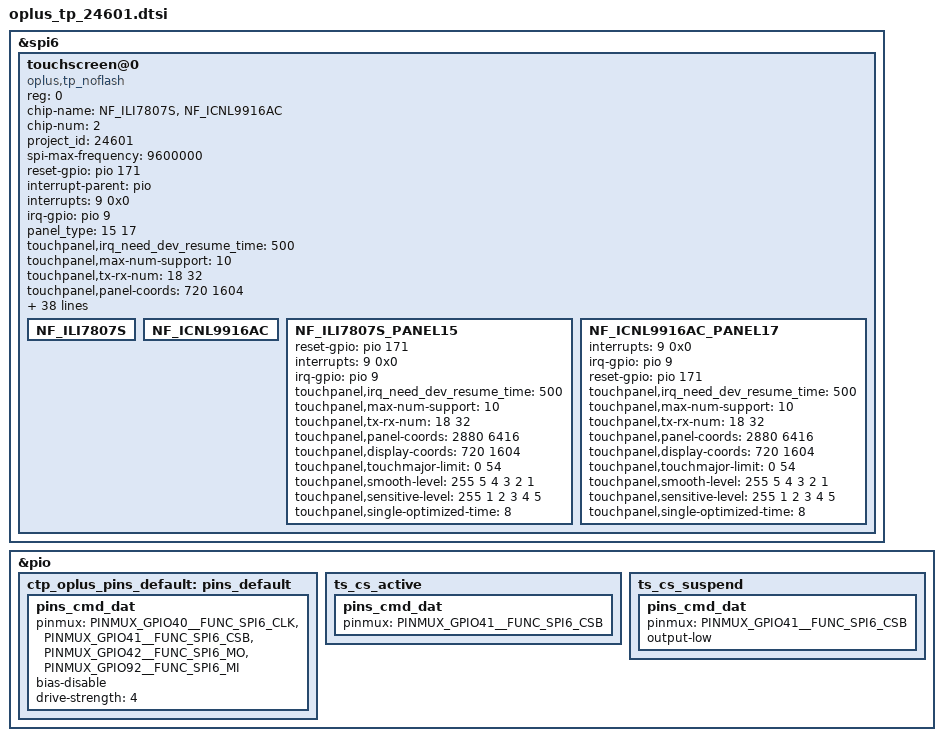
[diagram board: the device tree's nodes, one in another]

#include "mediatek/oplus-24601-tpfw.dtsi"
&spi6 {
	status = "okay";
	#address-cells = <1>;
	#size-cells = <0>;
	touchscreen@0 {
		compatible = "oplus,tp_noflash";
		reg = <0>;
		chip-name = "NF_ILI7807S","NF_ICNL9916AC";
		status = "ok";
		chip-num = <2>;

		project_id = <24601>;
		spi-max-frequency = <9600000>;    /*4800000,9600000,15000000,19200000*/
		reset-gpio = <&pio 171 0x00>;
		interrupt-parent = <&pio>;
		interrupts = <9  0x0>;
		irq-gpio = <&pio 9 0x2002>;

		panel_type = <15 17>;  /*type:20 HUIKE type:19 TONGXINGDA*/
		touchpanel,irq_need_dev_resume_time = <500>;
		touchpanel,max-num-support = <10>;
		touchpanel,tx-rx-num = <18 32>;			/*hd:18  32*/
		touchpanel,panel-coords = <720 1604>;
		touchpanel,display-coords = <720 1604>;	/*hd:720 1612*/
		touchpanel,touchmajor-limit = <0 54>;
		platform_support_project = <24601 24615 24617 24683 24722 24723 24727 24745 24746 24747>;
		platform_support_project_dir = <24601 24601 24601 24601 24601 24601 24601 24601 24601 24601>;
		platform_support_project_commandline ="oplus24601_hkc_ili9883c_hd_dsi_vdo_lcm_drv","oplus24601_djn_icnl9916ac_hd_dsi_vdo_lcm_drv";	/* hd*/
		firmware_name = "0xAB879HK00","0xAB879DJ00";
		pinctrl-names = "default", "pin_cs_high","pin_cs_low";
		pinctrl-0 = <&ctp_oplus_pins_default>;
		pinctrl-1 = <&ts_cs_active>;
		pinctrl-2 = <&ts_cs_suspend>;

		touchpanel,smooth-level = <255 5 4 3 2 1>;
		touchpanel,sensitive-level = <255 1 2 3 4 5>;
		touchpanel,single-optimized-time = <8>;

		incell_screen;
		irq_need_dev_resume_ok;
		fw_edge_limit_support;
		black_gesture_support;
		charger_pump_support;
		//headset_pump_support;
		esd_handle_support;
		//spurious_fingerprint_support;
		//lcd_trigger_fp_check;
		black_gesture_test_support;
		noflash_support;
		smart_gesture_support;
		pressure_report_support;
		fw_update_app_support;
		game_switch_support;
		drlimit_remove_support;
		lcd_trigger_load_tp_fw_support;
		suspend_gesture_cfg;
		//fw_update_in_probe_with_headfile;
		health_monitor_support;
		//auto_test_force_pass_support;
		exception_upload_support;
		report_rate_white_list_support;
		touchpanel,button-type = <4>;
		palm_to_sleep_support;
		diaphragm_touch_support;
		waterproof_support;

		NF_ILI7807S {

		};

		NF_ICNL9916AC {

		};
		NF_ILI7807S_PANEL15 {
			reset-gpio = <&pio 171 0x00>;
			interrupts = <9  0x0>;
			irq-gpio = <&pio 9 0x2002>;

			touchpanel,irq_need_dev_resume_time = <500>;
			touchpanel,max-num-support = <10>;
			touchpanel,tx-rx-num = <18 32>;			/*hd:18  32*/
			touchpanel,panel-coords = <2880 6416>;
			touchpanel,display-coords = <720 1604>;	/*hd:720 1612*/
			touchpanel,touchmajor-limit = <0 54>;
			touchpanel,smooth-level = <255 5 4 3 2 1>;
			touchpanel,sensitive-level = <255 1 2 3 4 5>;
			touchpanel,single-optimized-time = <8>;
		};

		NF_ICNL9916AC_PANEL17 {
			interrupts = <9  0x0>;
			irq-gpio = <&pio 9 0x2002>;
			reset-gpio = <&pio 171 0x00>;

			touchpanel,irq_need_dev_resume_time = <500>;
			touchpanel,max-num-support = <10>;
			touchpanel,tx-rx-num = <18 32>;			/*hd:18  32*/
			touchpanel,panel-coords = <2880 6416>;
			touchpanel,display-coords = <720 1604>;	/*hd:720 1612*/
			touchpanel,touchmajor-limit = <0 54>;
			touchpanel,smooth-level = <255 5 4 3 2 1>;
			touchpanel,sensitive-level = <255 1 2 3 4 5>;
			touchpanel,single-optimized-time = <8>;
		};
	};
};

&pio {
	ctp_oplus_pins_default: pins_default {
		pins_cmd_dat {
			pinmux = <PINMUX_GPIO40__FUNC_SPI6_CLK>,
					<PINMUX_GPIO41__FUNC_SPI6_CSB>,
					<PINMUX_GPIO42__FUNC_SPI6_MO>,
					<PINMUX_GPIO92__FUNC_SPI6_MI>;
			bias-disable;
			drive-strength = <4>;
		};
	};
	ts_cs_active: ts_cs_active {
		pins_cmd_dat {
			pinmux = <PINMUX_GPIO41__FUNC_SPI6_CSB>;
		};
	};
	ts_cs_suspend: ts_cs_suspend {
		pins_cmd_dat {
			pinmux = <PINMUX_GPIO41__FUNC_SPI6_CSB>;
			output-low;
		};
	};
};

